# GD32C231 register map
File version: 1.0
CPU: CM23 r0p0, little endian, MPU, FPU, 4 interrupt priority bits
Registers are 32-bit, read-write, reset 0x0 unless marked. A register's access mark holds for its fields unless they carry their own. Offsets are from the block's base; [hi:lo] are bit positions; {n}, {i} and the like mark numbered series.

## ADC — Analog-to-digital converter
Base 0x40012400
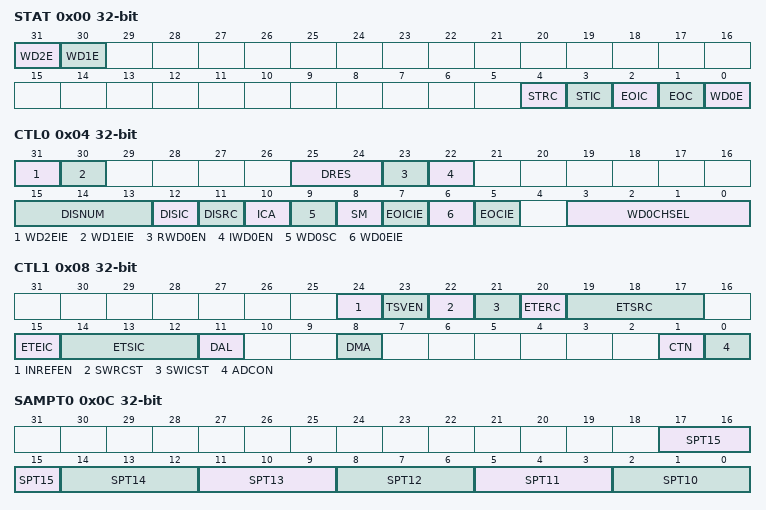
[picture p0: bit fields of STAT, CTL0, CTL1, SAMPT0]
0x00 STAT — Status register
  [31] WD2E — Analog watchdog 2 event flag
  [30] WD1E — Analog watchdog 1 event flag
  [4] STRC — Start flag of routine sequence
  [3] STIC — Start flag of inserted sequence
  [2] EOIC — End flag of inserted sequence conversion
  [1] EOC — End flag of sequence conversion
  [0] WD0E — Analog watchdog 0 event flag
0x04 CTL0 — Control register 0
  [31] WD2EIE — Interrupt enable for WD2E
  [30] WD1EIE — Interrupt enable for WD1E
  [25:24] DRES — ADC resolution
  [23] RWD0EN — Routine channel analog watchdog 0 enable
  [22] IWD0EN — Inserted channel analog watchdog 0 enable
  [15:13] DISNUM — Number of conversions in discontinuous mode
  [12] DISIC — Discontinuous mode on inserted sequence
  [11] DISRC — Discontinuous mode on routine sequence
  [10] ICA — Inserted sequence convert automatically
  [9] WD0SC — When in scan mode, analog watchdog 0 is effective on a single channel.
  [8] SM — Scan mode
  [7] EOICIE — Interrupt enable for EOIC
  [6] WD0EIE — Interrupt enable for WD0E
  [5] EOCIE — Interrupt enable for EOC
  [3:0] WD0CHSEL — Analog watchdog 0 channel select
0x08 CTL1 — Control register 1
  [24] INREFEN — Internal reference voltage channel (VREFINT) enable
  [23] TSVEN — Temperature sensor output voltage channel (VSENSE) enable
  [22] SWRCST — Software start of routine sequence
  [21] SWICST — Software start on inserted sequence.
  [20] ETERC — External trigger enable for routine sequence
  [19:17] ETSRC — External trigger selection for routine sequence
  [15] ETEIC — External trigger enable for inserted sequence
  [14:12] ETSIC — External trigger selection for inserted sequence
  [11] DAL — Data alignment
  [8] DMA — DMA request enable
  [1] CTN — Continuous mode
  [0] ADCON
0x0C SAMPT0 — Sample time register 0
  [3n-28:3n-30] SPT{n} (n=11..15) — Refer to SPT10[2:0] description.
  [2:0] SPT10 — Channel sample time
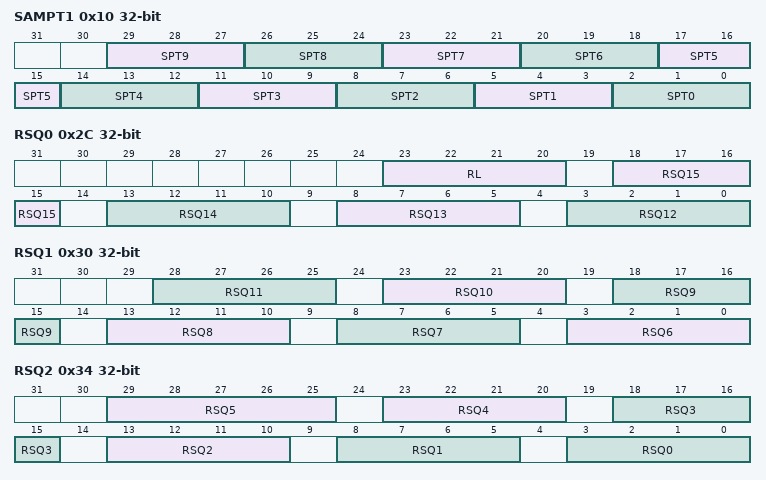
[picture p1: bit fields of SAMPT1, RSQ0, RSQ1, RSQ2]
0x10 SAMPT1 — Sample time register 1
  [3n+2:3n] SPT{n} (n=1..9) — Refer to SPT0[2:0] description
  [2:0] SPT0 — Channel sample time
{0x14+4i} IOFF{i} (i=0..3) — Inserted channel data offset register {i}
  [11:0] IOFF — Data offset for inserted channel x
0x24 WD0HT reset 0xFFF — Watchdog 0 high threshold register
  [11:0] WD0HT — High threshold for analog watchdog 0
0x28 WD0LT — Watchdog 0 low threshold register
  [11:0] WD0LT — Low threshold for analog watchdog 0
0x2C RSQ0 — Routine sequence register 0
  [23:20] RL — Routine sequence length
  [5n-57:5n-60] RSQ{n} (n=12..15) — Refer to RSQ0[3:0] description
0x30 RSQ1 — Routine sequence register 1
  [5n-27:5n-30] RSQ{n} (n=6..11) — Refer to RSQ0[3:0] description
0x34 RSQ2 — Routine sequence register 2
  [29:25] RSQ5 — Refer to RSQ0[3:0] description
  [5n+3:5n] RSQ{n} (n=1..4) — Refer to RSQ0[3:0] description
  [3:0] RSQ0 — The channel number is written to these bits to select a channel as the nth conversion in the routine sequence.
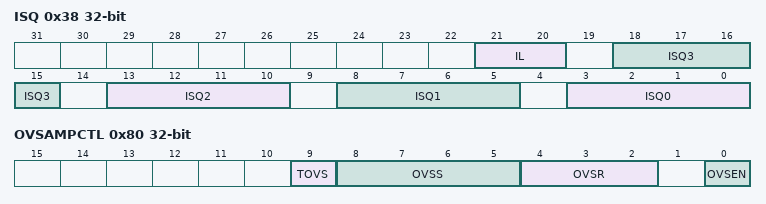
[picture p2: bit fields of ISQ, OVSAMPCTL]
0x38 ISQ — Inserted sequence register
  [21:20] IL — Inserted sequence length
  [18:15] ISQ3 — Refer to ISQ0[3:0] description
  [13:10] ISQ2 — Refer to ISQ0[3:0] description
  [8:5] ISQ1 — Refer to ISQ0[3:0] description
  [3:0] ISQ0 — The channel number is written to these bits to select a channel at the nth conversion in the inserted sequence.
{0x3C+4i} IDATA{i} ro (i=0..3) — Inserted data register {i}
  [15:0] IDATAn — Inserted number n conversion data
0x4C RDATA ro — Routine data register
  [15:0] RDATA — Routine channel data
0x50 WD1SR — Watchdog 1 channel selection register
  [15:0] AWD1CS — Analog watchdog 1 channel selection
0x54 WD2SR — Watchdog 2 channel selection register
  [15:0] AWD2CS — Analog watchdog 2 channel selection
0x58 WD1HT reset 0xFFF — Watchdog 1 high threshold register1
  [11:0] WD1HT — High threshold for analog watchdog 1
0x5C WD1LT — Watchdog 1 low threshold register1
  [11:0] WD1LT — Low threshold for analog watchdog 1
0x60 WD2HT reset 0xFFF — Watchdog 2 high threshold register2
  [11:0] WD2HT — High threshold for analog watchdog 2
0x64 WD2LT — Watchdog 2 low threshold register2
  [11:0] WD2LT — Low threshold for analog watchdog 2
0x80 OVSAMPCTL — Oversample control register
  [9] TOVS — Triggered oversampling
  [8:5] OVSS — Oversampling shift
  [4:2] OVSR — Oversampling ratio
  [0] OVSEN — Oversampler enable
